# A31L12x register map
Vendor: VENDOR ABOV Semiconductor Co., Ltd.; Series: A31L12x; File version: 1.0
CPU: CM0+ r0p1, little endian, no MPU, no FPU, VTOR, 2 interrupt priority bits
Registers are 32-bit, read-write, reset 0x0 unless marked. A register's access mark holds for its fields unless they carry their own. Offsets are from the block's base; [hi:lo] are bit positions; {n}, {i} and the like mark numbered series.

## USART1n — USART 1n (UART + SPI)
Base 0x54000000
Same registers: USART10 0x40003800
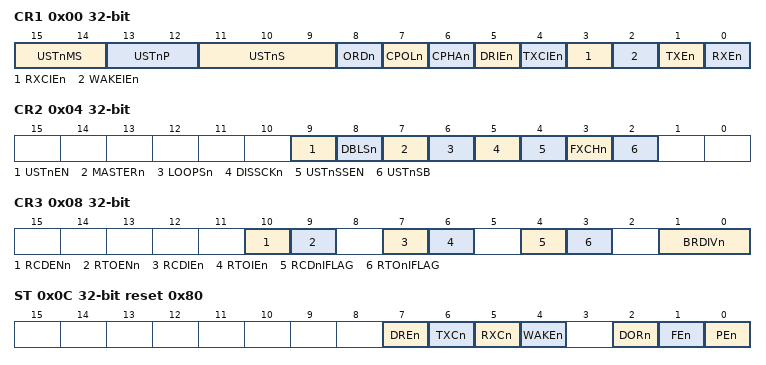
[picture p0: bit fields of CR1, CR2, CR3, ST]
0x00 CR1 — USART1n Control Register 1
  [15:14] USTnMS — USART1n Operation Mode Selection
    0=Asynchronous Mode (UART); 1=Synchronous Mode (USRT); 3=SPI (SPI Mode)
  [13:12] USTnP — Selects Parity Generation and Check method (only UART mode)
    0=No (No Parity); 2=Even Parity; 3=Odd (Odd Parity)
  [11:9] USTnS — Selects the length of data bit in a frame when Asynchronous or Synchronous mode
    {v}={v+5}bit (v=0..3); 7=9bit
  [8] ORDn — Selects the first data bit to be transmitted (only SPI mode)
    0=lsbFirst; 1=msbFirst
  [7] CPOLn — Selects the Clock Polarity of ACK in Synchronous or SPI mode
    0=IdleLow (SCK to 0 when idle); 1=IdleHigh (SCK to 1 when idle)
  [6] CPHAn — The CPOLn and this bit determine if data are sampled on the leading or trailing edge of SCK (only SPI mode)
    0=StartIdle (Start with idle state.); 1=StartInverted (Start with inverted idle state.)
  [5] DRIEn — Transmit Data Register Empty Interrupt Enable
  [4] TXCIEn — Transmit Complete Interrupt Enable
  [3] RXCIEn — Receive Complete Interrupt Enable
  [2] WAKEIEn — Asynchronous Wake-Up Interrupt Enable in Deep Sleep Mode (only UART mode)
  [1] TXEn — Enable the transmitter unit.
  [0] RXEn — Enable the receiver unit.
0x04 CR2 — USART1n Control Register 2
  [9] USTnEN — Activate USART1n Block by supplying
  [8] DBLSn — Selects receiver sampling rate (only UART mode)
  [7] MASTERn — Selects master or slave in SPI or Synchronous mode and controls the direction of SCK pin
  [6] LOOPSn — 1-wire Half-Duplex Communication on Asynchronous Mode or Loop Back for Test on SPI and Asynchronous Mode
  [5] DISSCKn — In synchronous mode operation, selects the waveform of SCK output
  [4] USTnSSEN — This bit controls the SS pin operation (only SPI mode)
  [3] FXCHn — SPI port function exchange control bit (only SPI mode)
  [2] USTnSB — Selects the length of stop bit in Asynchronous or Synchronous mode
0x08 CR3 — USART1n Control Register 3
  [10] RCDENn — Receive Character Detection Function Enable
  [9] RTOENn — Receive Time Out Function Enable
  [7] RCDIEn — Receive Character Detection Interrupt Enable
  [6] RTOIEn — Receive Time Out Interrupt Enable
  [4] RCDnIFLAG — Receive Character detection Interrupt Flag
  [3] RTOnIFLAG — Receive Time Out Interrupt Flag
  [1:0] BRDIVn — Baud Rate Clock Dividing Selection for Receive Time Out bits (only asynchronous mode)
0x0C ST reset 0x80 — USART1n Status Register
  [7] DREn — Transmit Data Register Empty Interrupt Flag
  [6] TXCn — Transmit Complete Interrupt Flag
  [5] RXCn — Receive Complete Interrupt Flag
  [4] WAKEn — Asynchronous Wake-Up Interrupt Flag
  [2] DORn — Data Overrun
  [1] FEn — Frame Error
  [0] PEn — Parity Error
0x10 BDR reset 0xFFF — USART1n Baud Rate Generation Register
  [11:0] BDATA — The value in this register is used to generate internal baud rate in UART mode or to generate SCK clock in SPI mode
0x14 RDR ro — USART1n Receive Data Register
  [8:0] RDATA — Receive Data
0x18 TDR — USART1n Transmit Data Register
  [8:0] TDATA — Transmit Data
0x1C RTODR reset 0xFF — USART1n Receive Time Out Data Register
  [7:0] RTOD — USART1n Receive Time Out Data
0x20 RCDR — USART1n Receive Character Detection Data Register
  [7:0] RCDD — USART1n Receive Character Detection Data

## UARTn
Base 0x55000000
Same registers: UART0 0x40004000, UART1 0x40004100
0x00 RBR ro — UARTn Receive Data Buffer Register
  [7:0] RBR — UARTn Receive Data Buffer
0x00 THR wo — UARTn Transmit Data Hold Register
  [7:0] THR — UARTn Transmit Data Hold
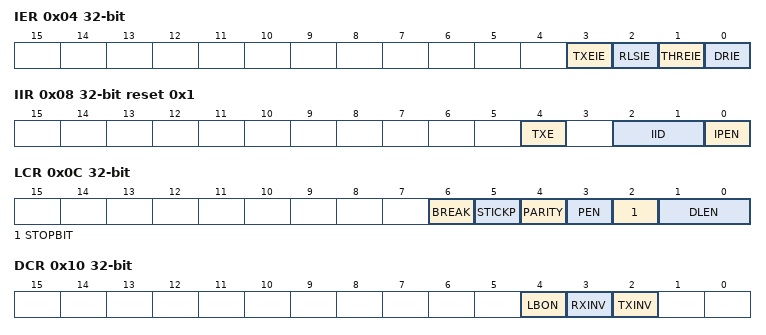
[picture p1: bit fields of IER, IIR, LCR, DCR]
0x04 IER — UARTn Interrupt Enable Register
  [3] TXEIE — Transmit Empty Interrupt Enable
  [2] RLSIE — Receiver Line Status Interrupt Enable
  [1] THREIE — Transmit Holding Register Empty Interrupt Enable
  [0] DRIE — Data Receive Interrupt Enable
0x08 IIR ro reset 0x1 — UARTn Interrupt ID Register
  [4] TXE — Transmit Complete Interrupt Source ID
  [2:1] IID — UARTn Interrupt ID
  [0] IPEN — Interrupt Pending
0x0C LCR — UARTn Line Control Register
  [6] BREAK — Transfer Break Control
  [5] STICKP — Force Parity
  [4] PARITY — Parity Mode and Parity Stuck Selection
  [3] PEN — Parity Bit Transfer Enable
  [2] STOPBIT — Stop Bit Length Selection
  [1:0] DLEN — Data Length Selection
0x10 DCR — UARTn Data Control Register
  [4] LBON — Local Loopback Test Mode Enable
  [3] RXINV — Receive Data Inversion Selection
  [2] TXINV — Transmit Data Inversion Selection
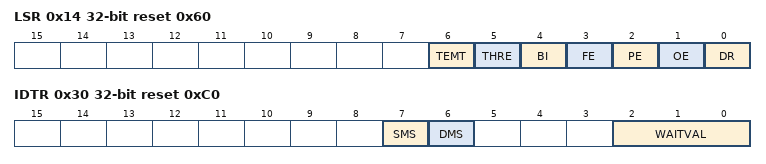
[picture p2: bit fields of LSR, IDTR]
0x14 LSR ro reset 0x60 — UARTn Line Status Register
  [6] TEMT — Transmit Empty
  [5] THRE — Transmit Holding Empty
  [4] BI — Break Condition Indication
  [3] FE — Frame Error Indicator
  [2] PE — Parity Error Indicator
  [1] OE — Overrun Error Indicator
  [0] DR — Data Receive Indicator
0x20 BDR — UARTn Baud Rate Divisor Latch Register
  [15:0] BDR — Baud Rate Divider Latch Value. Baud rate = fUARTnCLK/(16 x BDR[15:0] x 2)
0x24 BFR — UARTn Baud Rate Fractional Counter Value
  [7:0] BFR — Fraction Counter value
    0=Disable fraction counter
0x30 IDTR reset 0xC0 — UARTn Inter-frame Delay Time Register
  [7] SMS — Start Bit Multi Sampling Enable
  [6] DMS — Data Bit Multi sampling enable
  [2:0] WAITVAL — Wait Time Value
